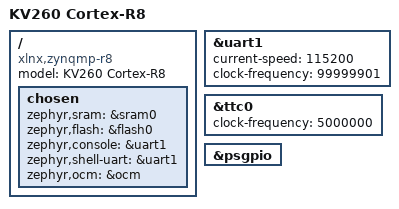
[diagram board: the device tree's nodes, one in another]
/*
 * Copyright (c) 2022 Linaro.
 * Copyright (c) 2024 Antmicro <www.antmicro.com>
 *
 * SPDX-License-Identifier: Apache-2.0
 *
 */

/dts-v1/;
#include <arm/xilinx/zynqmp_rpu_r8.dtsi>

/ {
	model = "KV260 Cortex-R8";
	compatible = "xlnx,zynqmp-r8";

	chosen {
		zephyr,sram = &sram0;
		zephyr,flash = &flash0;
		zephyr,console = &uart1;
		zephyr,shell-uart = &uart1;
		zephyr,ocm = &ocm;
	};
};

&uart1 {
	status = "okay";
	current-speed = <115200>;
	clock-frequency = <99999901>;
};

&ttc0 {
	status = "okay";
	clock-frequency = <5000000>;
};

&psgpio {
	status = "okay";
};
